# DMTIMER_1MS register map
Vendor: Texas Instruments
Peripheral module from a debugger description file (folder am437x).
Registers are 32-bit, read-write, no defined reset value unless marked. A register's access mark holds for its fields unless they carry their own. Offsets are as the file gives them; lines under a group give offsets from that group; [hi:lo] are bit positions; {n}, {i} and the like mark numbered series; 'fields as' and 'values as' point back to an identical list; <NAME> marks a mode.

## DMTIMER_1MS
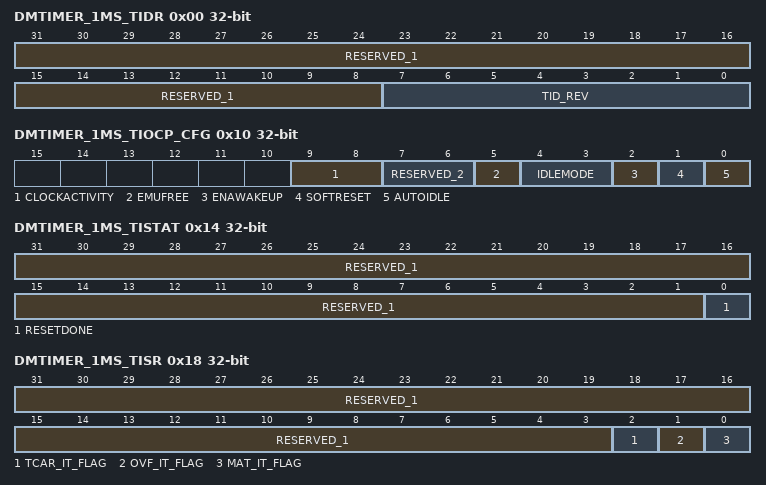
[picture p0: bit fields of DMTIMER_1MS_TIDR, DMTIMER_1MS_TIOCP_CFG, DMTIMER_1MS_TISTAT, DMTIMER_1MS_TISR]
0x00 DMTIMER_1MS_TIDR ro — This register contains the IP revision code
  [31:8] RESERVED_1 — Reads return 0
  [7:0] TID_REV — IP revision [[br]][7:4] Major revision [[br]][3:0] Minor revision Examples: 0x10 for 1.0, 0x21 for 2.1
0x10 DMTIMER_1MS_TIOCP_CFG — This register controls the various parameters of the OCP interface
  [9:8] CLOCKACTIVITY
  [7:6] RESERVED_2 — Write 0's for future compatibility Reads return 0
  [5] EMUFREE — Sensitivity to emulation (debug) suspend event from Debug Subsystem.
    1=en_2_0x1 (Timer counter free-running. Debug suspend event is ignored.); 0=en_1_0x0 (Timer counter frozen during a debug suspend event.)
  [4:3] IDLEMODE — Power Management, req/ack control
    3=en_4_0x3 (reserved do not use); 2=en_3_0x2 (Smart-idle. Acknowledgement to an idle request is given based on the internal activity of the module. The module may generate wakeup events when in idle state.); 1=en_2_0x1 (No-idle. An idle request is never acknowledged); 0=en_1_0x0 (Force-idle. An idle request is acknowledged unconditionally)
  [2] ENAWAKEUP — Wake-up feature global control
    1=en_2_0x1 (Wakeup line assertion enabled in smart-idle mode); 0=en_1_0x0 (No wakeup line assertion in idle mode)
  [1] SOFTRESET — Software reset. [[br]]This bit is automatically reset by the hardware. [[br]]During reads, it always return 0
    1=en_2_0x1 (The module is reset); 0=en_1_0x0 (Normal mode)
  [0] AUTOIDLE — Internal OCP clock gating strategy
    1=en_2_0x1 (Automatic OCP clock gating strategy is applied, based on the OCP interface activity); 0=en_1_0x0 (OCP clock is free-running)
0x14 DMTIMER_1MS_TISTAT ro — This register provides status information about the module, excluding the interrupt status information
  [31:1] RESERVED_1 — Reads return 0 Reserved for OCP-socket status information
  [0] RESETDONE — Internal reset monitoring
    1=en_2_0x1 (Reset completed); 0=en_1_0x0 (Internal module reset in on-going)
0x18 DMTIMER_1MS_TISR access per field — The Timer Status Register is used to determine which of the timer events requested an interrupt.
  [31:3] RESERVED_1 ro — Reads return 0
  [2] TCAR_IT_FLAG rw — indicates when an external pulse transition of the correct polarity is detected on the external pin PIEVENTCAPT
    1=en_2_0x1 (capture interrupt request); 0=en_1_0x0 (no capture interrupt request)
  [1] OVF_IT_FLAG rw — TCRR overflow
    1=en_2_0x1 (overflow interrupt pending); 0=en_1_0x0 (no overflow interrupt request)
  [0] MAT_IT_FLAG rw — the compare result of TCRR and TMAR
    1=en_2_0x1 (compare interrupt pending); 0=en_1_0x0 (no compare interrupt request)
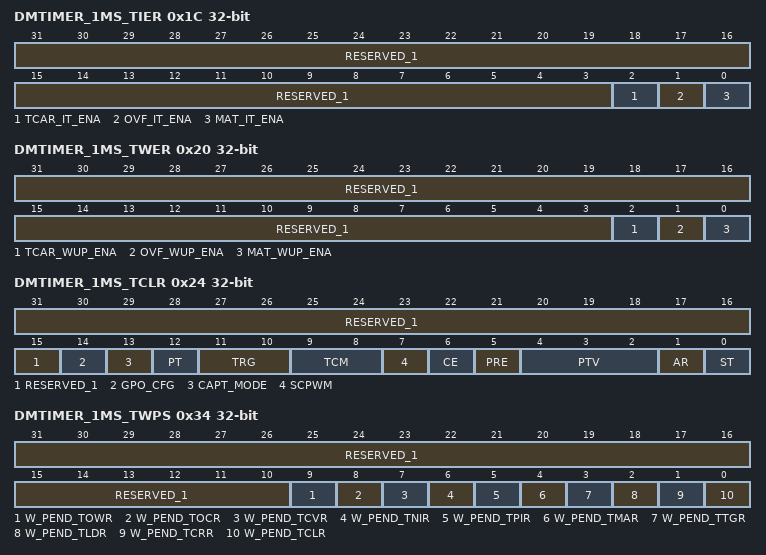
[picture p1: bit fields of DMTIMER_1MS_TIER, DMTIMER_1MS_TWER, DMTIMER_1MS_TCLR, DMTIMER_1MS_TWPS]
0x1C DMTIMER_1MS_TIER access per field — This register controls (enable/disable) the interrupt events
  [31:3] RESERVED_1 ro — Reads return 0
  [2] TCAR_IT_ENA rw — Enable capture interrupt
    1=en_2_0x1 (Enable capture interrupt); 0=en_1_0x0 (Disable capture interrupt)
  [1] OVF_IT_ENA rw — Enable overflow interrupt
    1=en_2_0x1 (Enable overflow interrupt); 0=en_1_0x0 (Disable overflow interrupt)
  [0] MAT_IT_ENA rw — Enable match interrupt
    1=en_2_0x1 (Enable match interrupt); 0=en_1_0x0 (Disable match interrupt)
0x20 DMTIMER_1MS_TWER access per field — This register controls (enable/disable) the wakeup feature on specific interrupt events
  [31:3] RESERVED_1 ro — Reads return 0
  [2] TCAR_WUP_ENA rw — Enable capture wake-up
    1=en_2_0x1 (Enable capture wake-up); 0=en_1_0x0 (Disable capture wake-up)
  [1] OVF_WUP_ENA rw — Enable overflow wake-up
    1=en_2_0x1 (Enable overflow wake-up); 0=en_1_0x0 (Disable overflow wake-up)
  [0] MAT_WUP_ENA rw — Enable match wake-up
    1=en_2_0x1 (Enable match wake-up); 0=en_1_0x0 (Disable match wake-up)
0x24 DMTIMER_1MS_TCLR access per field — This register controls optional features specific to the timer functionality
  [31:15] RESERVED_1 ro — Reads return 0
  [14] GPO_CFG rw
  [13] CAPT_MODE rw — Capture mode select bit (first/second)
    1=en_2_0x1 (Capture the second enabled capture event in TCAR2); 0=en_1_0x0 (Capture the first enabled capture event in TCAR1)
  [12] PT rw — Pulse or Toggle select bit
    1=en_2_0x1 (toggle modulation); 0=en_1_0x0 (pulse modulation)
  [11:10] TRG rw — Trigger Output Mode
    3=en_4_0x3 (Reserved); 2=en_3_0x2 (Overflow and match trigger); 1=en_2_0x1 (Overflow trigger); 0=en_1_0x0 (No trigger)
  [9:8] TCM rw — Transition Capture Mode
    3=en_4_0x3 (Capture on booth edges of PIEVETCAPT); 2=en_3_0x2 (Capture on falling edges of PIEVETCAPT); 1=en_2_0x1 (Capture on rising edges of PIEVETCAPT); 0=en_1_0x0 (No capture)
  [7] SCPWM rw — Pulse Width Modulation output pin default value
    1=en_2_0x1 (default value of PORPWM: 1); 0=en_1_0x0 (default value of PORPWM: 0)
  [6] CE rw — Compare enable
    1=en_2_0x1 (Compare enabled); 0=en_1_0x0 (Compare disabled)
  [5] PRE rw — Prescaler enable
    1=en_2_0x1 (Prescaler enabled); 0=en_1_0x0 (Prescaler disabled)
  [4:2] PTV rw — Trigger Output Mode
  [1] AR rw — Auto-reload mode
    1=en_2_0x1 (Auto-reload mode overflow); 0=en_1_0x0 (One shot mode overflow)
  [0] ST rw — Start/Stop timer control
    1=en_2_0x1 (Start the timer); 0=en_1_0x0 (Stop the timer)
0x28 DMTIMER_1MS_TCRR — This register holds the value of the internal counter
  [31:0] TIMER_CTR — The value of the timer counter register
0x2C DMTIMER_1MS_TLDR — This register holds the timer's load value
  [31:0] LOAD_VALUE — The value of the timer load register
0x30 DMTIMER_1MS_TTGR — This register triggers a counter reload of timer by writing any value in it.
  [31:0] TTGR_VALUE — The value of the trigger register During reads, it always returns "0xFFFFFFFF"
0x34 DMTIMER_1MS_TWPS ro — This register contains the write posting bits for all writ-able functional registers
  [31:10] RESERVED_1 — Reads return 0
  [9] W_PEND_TOWR — Write pending for register TOWR
    1=en_2_0x1 (Overflow Wrapping Register write pending.); 0=en_1_0x0 (No Overflow Wrapping Register write pending.)
  [8] W_PEND_TOCR — Write pending for register TOCR
    1=en_2_0x1 (Overflow Counter Register write pending.); 0=en_1_0x0 (No Overflow Counter Register write pending.)
  [7] W_PEND_TCVR — Write pending for register TCVR
    1=en_2_0x1 (Counter Register write pending.); 0=en_1_0x0 (No Counter Register write pending.)
  [6] W_PEND_TNIR — Write pending for register TNIR
    1=en_2_0x1 (Negativ Increment Register write pending.); 0=en_1_0x0 (No Negativ Increment Register write pending.)
  [5] W_PEND_TPIR — Write pending for register TPIR
    1=en_2_0x1 (Positive Increment Register write pending.); 0=en_1_0x0 (No Positive Increment Register write pending.)
  [4] W_PEND_TMAR — Write pending for register TMAR
    1=en_2_0x1 (Match Register write pending); 0=en_1_0x0 (No Match Register write pending)
  [3] W_PEND_TTGR — Write pending for register TTGR
    1=en_2_0x1 (Trigger Register write pending); 0=en_1_0x0 (No Trigger Register write pending)
  [2] W_PEND_TLDR — Write pending for register TLDR
    1=en_2_0x1 (Load Register write pending); 0=en_1_0x0 (No Load Register write pending)
  [1] W_PEND_TCRR — Write pending for register TCRR
    1=en_2_0x1 (Counter Register write pending); 0=en_1_0x0 (No Counter Register write pending)
  [0] W_PEND_TCLR — Write pending for register TCLR
    1=en_2_0x1 (Control Register write pending); 0=en_1_0x0 (No Control Register write pending)
0x38 DMTIMER_1MS_TMAR — This register holds the match value to be compared with the counter's value
  [31:0] COMPARE_VALUE — The value of the match register
0x3C DMTIMER_1MS_TCAR1 ro — This register holds the value of the first counter register capture
  [31:0] CAPTURE_VALUE1 — The value of first captured counter register
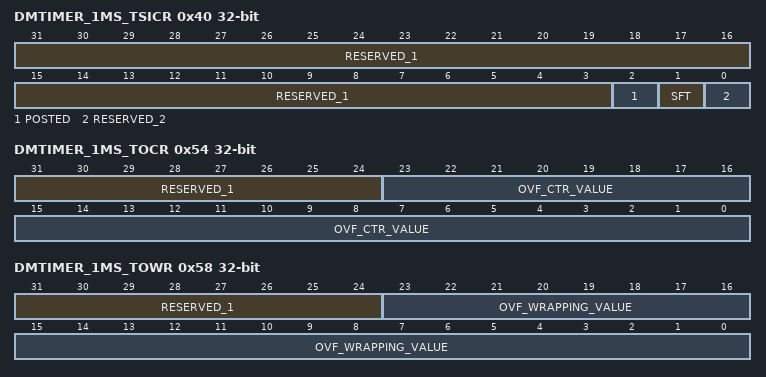
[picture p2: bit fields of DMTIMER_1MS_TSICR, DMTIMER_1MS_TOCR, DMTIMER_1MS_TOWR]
0x40 DMTIMER_1MS_TSICR access per field — Timer Synchronous Interface Control Register
  [31:3] RESERVED_1 ro — Reads return 0
  [2] POSTED rw — PIFREQRATIO
    1=en_2_0x1 (Posted mode active (clocks ratio needs to fit freq (timer) less than freq (OCP)/4 frequency requirement).); 0=en_1_0x0 (Posted mode inactive: will delay the command accept output signal. Note: This mode is not recommended on this device.)
  [1] SFT rw — This bit reset all the functional part of the module
    1=en_2_0x1 (software reset is enabled); 0=en_1_0x0 (software reset is disabled)
  [0] RESERVED_2 ro — Reads return 0
0x44 DMTIMER_1MS_TCAR2 ro — This register holds the value of the second counter register capture
  [31:0] CAPTURE_VALUE2 — The value of second captured counter register
0x48 DMTIMER_1MS_TPIR — This register is used for 1ms tick generation. The TPIR register holds the value of the positive increment. The value of this register is added with the value of the TCVR to define whether next value loaded in TCRR will be the sub-period value or the over-period value.
  [31:0] POSITIVE_INC_VALUE — The value of the positive increment.
0x4C DMTIMER_1MS_TNIR — This register is used for 1ms tick generation. The TNIR register holds the value of the negative increment. The value of this register is added with the value of the TCVR to define whether next value loaded in TCRR will be the sub-period value or the over-period value.
  [31:0] NEGATIVE_INV_VALUE — The value of the negative increment.
0x50 DMTIMER_1MS_TCVR — This register is used for 1ms tick generation. The TCVR register defines whether next value loaded in TCRR will be the sub-period value or the over-period value.
  [31:0] CTR_VALUE — The value of CVR counter.
0x54 DMTIMER_1MS_TOCR access per field — This register is used to mask the tick interrupt for a selected number of ticks.
  [31:24] RESERVED_1 ro — Reads return 0.
  [23:0] OVF_CTR_VALUE rw — The number of overflow events.
0x58 DMTIMER_1MS_TOWR access per field — This register holds the number of masked overflow interrupts.
  [31:24] RESERVED_1 ro — Reads return 0
  [23:0] OVF_WRAPPING_VALUE rw — The number of masked interrupts.
